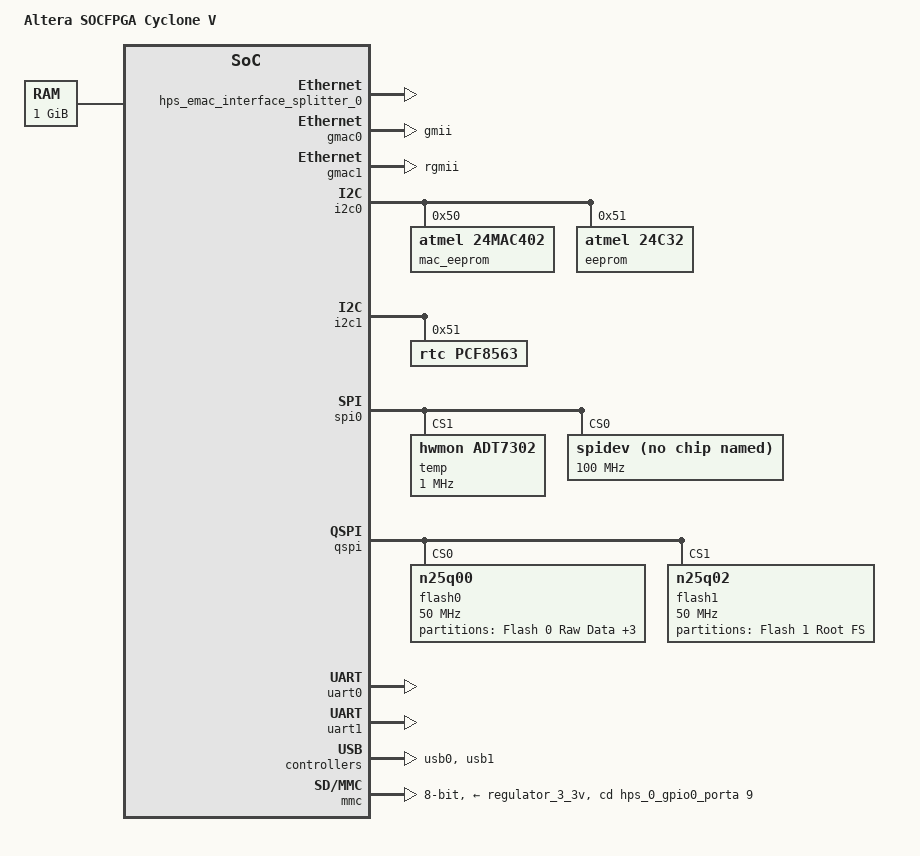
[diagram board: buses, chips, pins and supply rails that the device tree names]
/*
 * This devicetree is generated by sopc2dts version 15.1 [94267f754b718da09506aebbe5343be8fdba1582] on Thu May 04 12:59:35 PDT 2017
 * Sopc2dts is written by Walter Goossens <waltergoossens@home.nl>
 * in cooperation with the nios2 community <nios2-dev@lists.rocketboards.org>
 */
#include "socfpga_cyclone5.dtsi"

/ {
	model = "Altera SOCFPGA Cyclone V";	/* appended from boardinfo */
	compatible = "altr,socfpga-cyclone5", "altr,socfpga";	/* appended from boardinfo */

	chosen {
		bootargs = "earlyprintk";
		stdout-path = "serial0:115200n8";
	};

	memory {
		name = "memory";
		device_type = "memory";
		reg = <0x00000000 0x40000000>;
	}; //end memory

	aliases {
		serial0 = "&uart0";
		serial1 = "&uart1";
		serial2 = "&uart2";
		spi0 = "&spi0";
        ethernet0 = &gmac0;
        ethernet1 = &gmac1;
	}; //end aliases
};

&base_fpga_region {
	#address-cells = <1>;
	#size-cells = <1>;
	ranges = <0 0xff200000 0x00200000>;
	fpga-bridges = <&fpga_bridge0>;

	external-fpga-config;

	hps_emac_interface_splitter_0: splitter@0xff250000 {
		compatible = "altr,splitter-15.1", "altr,emac-splitter";
		reg = < 0x00050000 0x00000008 >;
		clocks = < &h2f_user0_clk >;
	}; //end splitter@0xff250000 (hps_emac_interface_splitter_0)

	Nighthawk_FPGA_IO_alt_vip_vfr_0: vip@0xff244000 {
		compatible = "ALTR,vip-frame-reader-14.0", "ALTR,vip-frame-reader-9.1";
		reg = < 0x00044000 0x00000080 >;
		interrupt-parent = < &intc >;
		interrupts = < 0 43 4 >;
		clocks = <&h2f_user0_clk>,  <&h2f_user0_clk>;
		clock-names = "clock_reset", "clock_master";
		max-width = < 800 >;    /* MAX_IMAGE_WIDTH type NUMBER */
		max-height = < 480 >;   /* MAX_IMAGE_HEIGHT type NUMBER */
		bits-per-color = < 8 >; /* BITS_PER_PIXEL_PER_COLOR_PLANE type NUMBER */
		colors-per-beat = < 4 >;    /* NUMBER_OF_CHANNELS_IN_PARALLEL type NUMBER */
		beats-per-pixel = < 1 >;    /* NUMBER_OF_CHANNELS_IN_SEQUENCE type NUMBER */
		mem-word-width = < 128 >;   /* MEM_PORT_WIDTH type NUMBER */
	}; //end vip@0xff244000 (Nighthawk_FPGA_IO_alt_vip_vfr_0)
};

&gmac0 {
	phy-mode = "gmii";
	snps,phy-addr = < 0xFFFFFFFF >;
	phy-addr = < 0xFFFFFFFF >;

	rxd0-skew-ps = <0>;
	rxd1-skew-ps = <0>;
	rxd2-skew-ps = <0>;
	rxd3-skew-ps = <0>;
	txen-skew-ps = <0>;
	txc-skew-ps = <3000>;
	rxdv-skew-ps = <0>;
	rxc-skew-ps = <3000>;
	max-frame-size = <3800>;
	tx-fifo-depth = <4096>;	/* embeddedsw.dts.params.tx-fifo-depth type NUMBER */
	rx-fifo-depth = <4096>;	/* embeddedsw.dts.params.rx-fifo-depth type NUMBER */
	altr,emac-splitter = <&hps_emac_interface_splitter_0>;	/* appended from boardinfo */
	status = "okay";
};

&gmac1 {
	status = "okay";
	phy-mode = "rgmii";
	snps,phy-addr = < 0xFFFFFFFF >;
	phy-addr = < 0xFFFFFFFF >;

	rxd0-skew-ps = <0>;
	rxd1-skew-ps = <0>;
	rxd2-skew-ps = <0>;
	rxd3-skew-ps = <0>;
	txen-skew-ps = <0>;
	txc-skew-ps = <3000>;
	rxdv-skew-ps = <0>;
	rxc-skew-ps = <3000>;
	max-frame-size = <3800>;
	tx-fifo-depth = <4096>;	/* embeddedsw.dts.params.tx-fifo-depth type NUMBER */
	rx-fifo-depth = <4096>;	/* embeddedsw.dts.params.rx-fifo-depth type NUMBER */
};

&mmc0 {
	status = "disabled";
};


&i2c0 {
	status = "ok";
	speed-mode = <0>;

	mac_eeprom@50 {
		compatible = "atmel,24mac402";
		reg = <0x00000050>;
		pagesize = <16>;	/* appended from boardinfo */
	}; //end atmel,24mac402@0x50 (mac_eeprom)

	eeprom@51 {
		compatible = "atmel,24c32";
		reg = <0x00000051>;
		pagesize = <32>;	/* appended from boardinfo */
	}; //end atmel,24c32@0x51 (eeprom)
}; //end i2c@0xffc04000 (hps_0_i2c0)

&i2c1 {
	status = "okay";
	speed-mode = <0>;

	rtc@51 {
		compatible = "rtc,pcf8563";
		reg = <0x51>;
	};
};


&spi0 {
	#address-cells = < 1 >;  
	#size-cells = < 0 >;  
	bus-num = < 0 >;   
	num-chipselect = < 4 >;  
	status = "okay";   

	temp@1 {
		compatible = "hwmon,adt7302";
		reg = < 1 >;  
		spi-max-frequency = < 1000000 >; 
		spi-cpha = <1>;	/* appended from boardinfo */
		spi-cpol = <1>;	/* appended from boardinfo */
		enable-dma = < 1 >; 
	};

	spidev@0 {
		compatible = "spidev";
		reg = < 0 >;
		spi-max-frequency = < 100000000 >;
		enable-dma = < 1 >;
	};
};

&qspi {
	status = "okay";
	flash0: n25q00@0 {
		#address-cells = <1>;
		#size-cells = <1>;
		compatible = "n25q00";  /* appended from boardinfo */
		reg = <0>;      /* chip select */
		spi-max-frequency = <50000000>;

		cdns,page-size = <256>;
		cdns,block-size = <16>;
		cdns,read-delay = <4>;
		cdns,tshsl-ns = <50>;
		cdns,tsd2d-ns = <50>;
		cdns,tchsh-ns = <4>;
		cdns,tslch-ns = <4>;

		part0: partition@0 {
			label = "Flash 0 Raw Data"; /* appended from boardinfo */
			reg = < 0x00000000 0x00800000 >;    /* appended from boardinfo */
		}; //end partition@0 (part0)

		part1: partition@800000 {
			label = "FPGA/RBF Image "; /* appended from boardinfo */
			reg = < 0x00800000 0x00600000 >;    /* appended from boardinfo */
		}; //end partition@800000 (part1)

		part2: partition@0E00000 {
			label = "FPGA Image";   /* appended from boardinfo */
			reg = < 0x0E00000 0x00200000 >;    /* appended from boardinfo */
		}; //end partition@3800000 (part2)

		part3: partition@3e00000 {
			label = "Flash 0 FS partition";  /* appended from boardinfo */
			reg = < 0x01000000 0x03000000 >;    /* appended from boardinfo */
		}; //end partition@3e00000 (part3)
	};

	flash1: n25q02@1 {
		#address-cells = <1>;
		#size-cells = <1>;
		compatible = "n25q02";
		reg = <1>;      /* chip select */
		spi-max-frequency = <50000000>;

		cdns,page-size = <256>;
		cdns,block-size = <16>;
		cdns,read-delay = <4>;
		cdns,tshsl-ns = <50>;
		cdns,tsd2d-ns = <50>;
		cdns,tchsh-ns = <4>;
		cdns,tslch-ns = <4>;

		part4: partition@0 {
			label = "Flash 1 Root FS"; /* appended from boardinfo */
			reg = < 0x00000000 0x10000000 >;    /* appended from boardinfo */
		}; //end partition@0 (part4)
	}; //end n25q00@1 (flash1)
};

&uart0 {
	status = "okay";
};

&uart1 {
	status = "okay";
};

&usb0 {
	status = "okay";
};

&usb1 {
	status = "okay";
};

&gpio0 {
	status = "okay";
};

&gpio1 {
	status = "okay";
};

&gpio2 {
	status = "okay";
};

&mmc {
	status = "okay";
	num-slots = <1>;	/* embeddedsw.dts.params.num-slots type NUMBER */
	broken-cd;	/* appended from boardinfo */
	cap-mmc-highspeed;	/* appended from boardinfo */
	cap-sd-highspeed;	/* appended from boardinfo */
	cap-mmc_8bit_cap;	/* appended from boardinfo */
	u-boot,dm-pre-reloc;	/* appended from boardinfo */
	bus-width = <8>;	/* appended from boardinfo */
	altr,dw-mshc-ciu-div = <3>;	/* appended from boardinfo */
	altr,dw-mshc-sdr-timing = <0 3>;	/* appended from boardinfo */
	supports-highspeed;	/* appended from boardinfo */
	cd = <&hps_0_gpio0_porta 9 0>;	/* appended from boardinfo */
	cd-gpios = <&hps_0_gpio0_porta 9 0>;	/* appended from boardinfo */
	vmmc-supply = <&regulator_3_3v>;	/* appended from boardinfo */
	vqmmc-supply = <&regulator_3_3v>;	/* appended from boardinfo */

	slot_0: slot@0 {
		reg = <0>;	/* appended from boardinfo */
		bus-width = <8>;	/* appended from boardinfo */
	}; //end slot@0 (slot_0)
};
